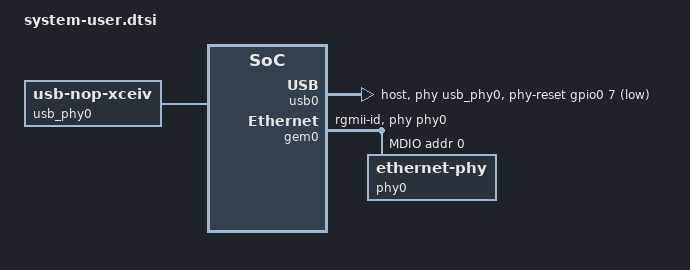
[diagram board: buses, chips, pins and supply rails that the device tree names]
/include/ "system-conf.dtsi"

/ {
    /* Define a standalone generic USB transceiver node */
    usb_phy0: usb_phy0 {
        compatible = "usb-nop-xceiv";
        #phy-cells = <0>;
    };
};

&usb0 {
    status = "okay";
    dr_mode = "host";
    phy_type = "ulpi";
    usb-phy = <&usb_phy0>;

    phy-reset-gpios = <&gpio0 7 1>;
    u-boot,dm-pre-reloc;
};

&gem0 {
    status = "okay";
    local-mac-address = [52 54 00 12 34 57];  // MAC address in hex
    phy-mode = "rgmii-id";
    phy-handle = <&phy0>;

    mdio {
        #address-cells = <1>;
        #size-cells = <0>;

        phy0: ethernet-phy@0 {
            reg = <0>;
        };
    };
};

&gem1 {
    status = "disabled";
};
